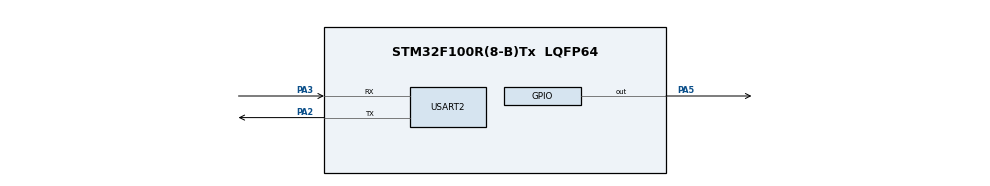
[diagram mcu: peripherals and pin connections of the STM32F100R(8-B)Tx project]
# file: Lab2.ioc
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Mcu.Family=STM32F1
Mcu.Name=STM32F100R(8-B)Tx
Mcu.Package=LQFP64
NVIC.PriorityGroup=NVIC_PRIORITYGROUP_4
PA13.Mode=Serial_Wire
PA13.Signal=SYS_JTMS-SWDIO
PA14.Mode=Serial_Wire
PA14.Signal=SYS_JTCK-SWCLK
PA2.Mode=Asynchronous
PA2.Signal=USART2_TX
PA3.Mode=Asynchronous
PA3.Signal=USART2_RX
PA5.Signal=GPIO_Output
ProjectManager.HeapSize=0x200
ProjectManager.StackSize=0x400
ProjectManager.TargetToolchain=STM32CubeIDE
RCC.APB1Freq_Value=8000000
RCC.APB2Freq_Value=8000000
USART2.VirtualMode=VM_ASYNC
board=custom

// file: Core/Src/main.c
/* USER CODE BEGIN Header */
/**
  ******************************************************************************
  * @file           : main.c
  * @brief          : Main program body
  ******************************************************************************
  * @attention
  *
  * <h2><center>&copy; Copyright (c) 2020 STMicroelectronics.
  * All rights reserved.</center></h2>
  *
  * This software component is licensed by ST under BSD 3-Clause license,
  * the "License"; You may not use this file except in compliance with the
  * License. You may obtain a copy of the License at:
  *                        opensource.org/licenses/BSD-3-Clause
  *
  ******************************************************************************
  */
/* USER CODE END Header */
#include "main.h"

UART_HandleTypeDef huart2;

/* USER CODE BEGIN PV */

uint8_t cliBufferTX[20];
uint8_t cliBufferRX[20];
uint8_t cmd[20];

/* USER CODE END PV */

void SystemClock_Config(void);
static void MX_GPIO_Init(void);
static void MX_USART2_UART_Init(void);
/* USER CODE BEGIN PFP */
void reset_buffer(void);
/* USER CODE END PFP */

/* USER CODE BEGIN 0 */

/*
 * resets the buffer of TX, RX, user command
 */
void reset_buffer()
{
  for (int i = 0; i < 20; ++i) {
	  cliBufferTX[i] = 0;
	  cliBufferRX[i] = 0;
	  cmd[i] = 0;
  }
}

/* USER CODE END 0 */

int main(void)
{

  /* MCU Configuration--------------------------------------------------------*/

  /* Reset of all peripherals, Initializes the Flash interface and the Systick. */
  HAL_Init();

  /* Configure the system clock */
  SystemClock_Config();

  /* Initialize all configured peripherals */
  MX_GPIO_Init();
  MX_USART2_UART_Init();
  /* USER CODE BEGIN 2 */

  uint8_t info1[] = "ENEL 487 Lab 2:\r\n";
  uint8_t info2[] = "CLI on the Target\r\n\r\n";

  uint8_t toggle[] = "toggle\r";
  uint8_t help[] = "help\r";
  uint8_t state[] = "state\r";
  uint8_t backspace[] = "\b";
  uint8_t double_enter[] = "\r\n\r\n";
  int cmd_counter;

  GPIO_PinState on_or_off;

  reset_buffer();

  //Displays some info in the beginning
  strcpy((char *) cliBufferTX, (char *) info1);
  HAL_UART_Transmit(&huart2, cliBufferTX, strlen((char *) cliBufferTX), 1000);
  strcpy((char *) cliBufferTX, info2);
  HAL_UART_Transmit(&huart2, cliBufferTX, strlen((char *) cliBufferTX), 1000);

  /* USER CODE END 2 */

  /* Infinite loop */
  /* USER CODE BEGIN WHILE */
  reset_buffer();

  while (1)
  {
	  cmd_counter = 0;
	  strcpy((char *) cliBufferTX, "Enter command: ");
	  HAL_UART_Transmit(&huart2, cliBufferTX, strlen((char *) cliBufferTX), 1000);
	  reset_buffer();

	  //will loop until user presses enter
	  while (cliBufferRX[0] != '\r'){
		  //only sends one character at a time -- tested sending multiple characters but I had trouble implementing it
		  if (HAL_UART_Receive(&huart2, cliBufferRX, 1, 10000) == HAL_OK) {
			  cliBufferTX[0] = cliBufferRX[0];

			  //check if user enters backspace
			  if (strcmp((char *) cliBufferTX, (char *) backspace) == 0){
				  cmd[cmd_counter] = 0;	//clears the element
				  --cmd_counter;

				  //if counter is less than zero, remain at zero so that it stays at the current line
				  if (cmd_counter < 0) {
					  cmd_counter = 0;
				  }
				  else {
					  HAL_UART_Transmit(&huart2, "\b \b", 3, 1000); //destructive backspace -- there may be a better way to do this
				  }
			  }
			  else {
				  //if not backspace, then enter it in the command line and increment it to next element and display
				  cmd[cmd_counter] = cliBufferTX[0];
				  ++cmd_counter;
				  HAL_UART_Transmit(&huart2, cliBufferTX, strlen((char *) cliBufferTX), 1000);
			  }
		  }
	  }

	  //checks which command the user entered
	  if  (strcmp((char *) cmd, (char *) toggle) == 0) {
		  strcpy((char *) cliBufferTX, "\r\nToggle light");
		  HAL_GPIO_TogglePin(GPIOA, GPIO_PIN_5);	//turns on the light
	  }
	  else if (strcmp((char *) cmd, (char *) help) == 0){
		  //Displays helpful commands to CLI
		  strcpy((char *) cliBufferTX, "\r\nUseful Commands:\r\n");
		  HAL_UART_Transmit(&huart2, cliBufferTX, strlen((char *) cliBufferTX), 1000);
		  strcpy((char *) cliBufferTX, "toggle : ");
		  HAL_UART_Transmit(&huart2, cliBufferTX, strlen((char *) cliBufferTX), 1000);
		  strcpy((char *) cliBufferTX, "turns LED on or off\r\n");
		  HAL_UART_Transmit(&huart2, cliBufferTX, strlen((char *) cliBufferTX), 1000);
		  strcpy((char *) cliBufferTX, "state : ");
		  HAL_UART_Transmit(&huart2, cliBufferTX, strlen((char *) cliBufferTX), 1000);
		  strcpy((char *) cliBufferTX, "displays the state of the LED");
	  }
	  else if (strcmp((char *) cmd, (char *) state) == 0){
		  //checks if the LED is on or off and lets the user know
		  on_or_off = HAL_GPIO_ReadPin(GPIOA, GPIO_PIN_5);
		  if (on_or_off == GPIO_PIN_RESET) {
			  strcpy((char *) cliBufferTX, "\r\nLED is OFF");
		  }
		  else if (on_or_off == GPIO_PIN_SET) {
			  strcpy((char *) cliBufferTX, "\r\nLED is ON");
		  }
	  }
	  else {
		  //user entered an invalid command
		  strcpy((char *) cliBufferTX, "\r\nInvalid command");
	  }

	  //display the output
	 HAL_UART_Transmit(&huart2, cliBufferTX, strlen((char *) cliBufferTX), 1000);
	 strcpy((char *) cliBufferTX, double_enter);
	 HAL_UART_Transmit(&huart2, cliBufferTX, strlen((char *) cliBufferTX), 1000);

	  HAL_Delay(5);

    /* USER CODE END WHILE */

  }
}

void SystemClock_Config(void)
{
  RCC_OscInitTypeDef RCC_OscInitStruct = {0};
  RCC_ClkInitTypeDef RCC_ClkInitStruct = {0};

  /** Initializes the RCC Oscillators according to the specified parameters
  * in the RCC_OscInitTypeDef structure.
  */
  RCC_OscInitStruct.OscillatorType = RCC_OSCILLATORTYPE_HSI;
  RCC_OscInitStruct.HSIState = RCC_HSI_ON;
  RCC_OscInitStruct.HSICalibrationValue = RCC_HSICALIBRATION_DEFAULT;
  RCC_OscInitStruct.PLL.PLLState = RCC_PLL_NONE;
  if (HAL_RCC_OscConfig(&RCC_OscInitStruct) != HAL_OK)
  {
    Error_Handler();
  }
  /** Initializes the CPU, AHB and APB buses clocks
  */
  RCC_ClkInitStruct.ClockType = RCC_CLOCKTYPE_HCLK|RCC_CLOCKTYPE_SYSCLK
                              |RCC_CLOCKTYPE_PCLK1|RCC_CLOCKTYPE_PCLK2;
  RCC_ClkInitStruct.SYSCLKSource = RCC_SYSCLKSOURCE_HSI;
  RCC_ClkInitStruct.AHBCLKDivider = RCC_SYSCLK_DIV1;
  RCC_ClkInitStruct.APB1CLKDivider = RCC_HCLK_DIV1;
  RCC_ClkInitStruct.APB2CLKDivider = RCC_HCLK_DIV1;

  if (HAL_RCC_ClockConfig(&RCC_ClkInitStruct, FLASH_LATENCY_0) != HAL_OK)
  {
    Error_Handler();
  }
}

static void MX_USART2_UART_Init(void)
{

  huart2.Instance = USART2;
  huart2.Init.BaudRate = 115200;
  huart2.Init.WordLength = UART_WORDLENGTH_8B;
  huart2.Init.StopBits = UART_STOPBITS_1;
  huart2.Init.Parity = UART_PARITY_NONE;
  huart2.Init.Mode = UART_MODE_TX_RX;
  huart2.Init.HwFlowCtl = UART_HWCONTROL_NONE;
  huart2.Init.OverSampling = UART_OVERSAMPLING_16;
  if (HAL_UART_Init(&huart2) != HAL_OK)
  {
    Error_Handler();
  }

}

static void MX_GPIO_Init(void)
{
  GPIO_InitTypeDef GPIO_InitStruct = {0};

  /* GPIO Ports Clock Enable */
  __HAL_RCC_GPIOA_CLK_ENABLE();

  /*Configure GPIO pin Output Level */
  HAL_GPIO_WritePin(GPIOA, GPIO_PIN_5, GPIO_PIN_RESET);

  /*Configure GPIO pin : PA5 */
  GPIO_InitStruct.Pin = GPIO_PIN_5;
  GPIO_InitStruct.Mode = GPIO_MODE_OUTPUT_PP;
  GPIO_InitStruct.Pull = GPIO_NOPULL;
  GPIO_InitStruct.Speed = GPIO_SPEED_FREQ_LOW;
  HAL_GPIO_Init(GPIOA, &GPIO_InitStruct);

}

void Error_Handler(void)
{
}

/************************ (C) COPYRIGHT STMicroelectronics *****END OF FILE****/
